AUTOSAR XML (schema 4-3-0)
package /ComponentTypes
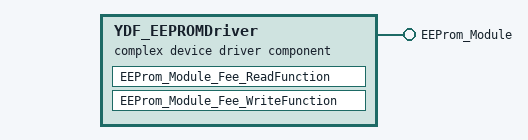
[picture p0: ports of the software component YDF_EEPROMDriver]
  complex device driver sw component type YDF_EEPROMDriver
    provide port EEProm_Module: provided-com-specs=[{operation=Fee_WriteFunction, queue-length=1}, {operation=Fee_ReadFunction, queue-length=1}], provided-interface=EEProm_Module
    behavior YDF_EEPROMDriver_InternalBehavior
      operation invoked event OIT_EEProm_Module_Fee_ReadFunction_EEProm_Module_Fee_ReadFunction: start-on-event=EEProm_Module_Fee_ReadFunction, operation=EEProm_Module.Fee_ReadFunction
      operation invoked event OIT_EEProm_Module_Fee_WriteFunction_EEProm_Module_Fee_WriteFunction: start-on-event=EEProm_Module_Fee_WriteFunction, operation=EEProm_Module.Fee_WriteFunction
      runnable EEProm_Module_Fee_ReadFunction
      runnable EEProm_Module_Fee_WriteFunction
  swc implementation YDF_EEPROMDriver_Implementation: behavior=YDF_EEPROMDriver_InternalBehavior
